# ESP32-P4 register map
Vendor: ESPRESSIF SYSTEMS (SHANGHAI) CO., LTD.; Series: ESP32 P-Series; File version: 2
CPU: RV32IMAFC r0p0, little endian, no MPU, FPU, 0 interrupt priority bits
Address unit: 32 bits
Registers are 32-bit, read-write, reset 0x0 unless marked. A register's access mark holds for its fields unless they carry their own. Offsets are from the block's base; [hi:lo] are bit positions; {n}, {i} and the like mark numbered series.

## TWAI0 — Two-Wire Automotive Interface
Base 0x500D7000
Same registers: TWAI1 0x500D8000, TWAI2 0x500D9000
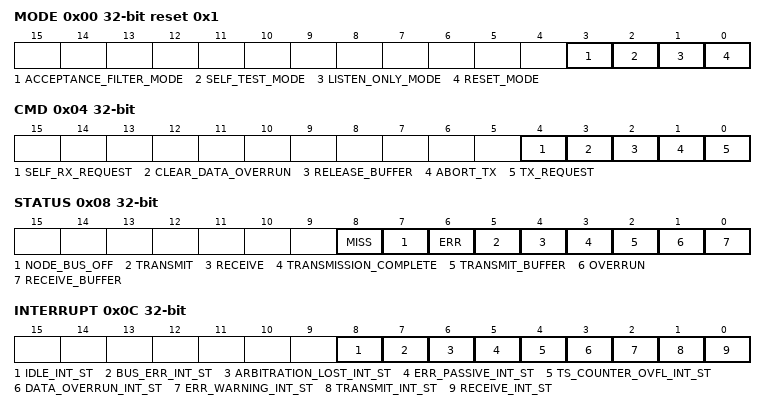
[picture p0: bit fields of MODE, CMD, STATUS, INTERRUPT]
0x00 MODE reset 0x1 — TWAI mode register.
  [3] ACCEPTANCE_FILTER_MODE — 1:single, the single acceptance filter option is enabled (one filter with the length of 32 bit is active). 0:dual, the dual acceptance filter option is enabled (two filters, each with the length of 16 bit are active).
  [2] SELF_TEST_MODE — 1: self test, in this mode a full node test is possible without any other active node on the bus using the self reception request command. The TWAI controller will perform a successful transmission, even if there is no acknowledge received. 0: normal, an acknowledge is required for successful transmission.
  [1] LISTEN_ONLY_MODE — 1: listen only, in this mode the TWAI controller would give no acknowledge to the TWAI-bus, even if a message is received successfully. The error counters are stopped at the current value. 0: normal.
  [0] RESET_MODE — 1: reset, detection of a set reset mode bit results in aborting the current transmission/reception of a message and entering the reset mode. 0: normal, on the '1-to-0' transition of the reset mode bit, the TWAI controller returns to the operating mode.
0x04 CMD wo — TWAI command register.
  [4] SELF_RX_REQUEST — 1: present, a message shall be transmitted and received simultaneously. 0: absent.
  [3] CLEAR_DATA_OVERRUN — 1: clear, the data overrun status bit is cleared. 0: no action.
  [2] RELEASE_BUFFER — 1: released, the receive buffer, representing the message memory space in the RXFIFO is released. 0: no action
  [1] ABORT_TX — 1: present, if not already in progress, a pending transmission request is cancelled. 0: absent
  [0] TX_REQUEST — 1: present, a message shall be transmitted. 0: absent
0x08 STATUS ro — TWAI status register.
  [8] MISS — 1: current message is destroyed because of FIFO overflow.
  [7] NODE_BUS_OFF — 1: bus-off, the TWAI controller is not involved in bus activities. 0: bus-on, the TWAI controller is involved in bus activities
  [6] ERR — 1: error, at least one of the error counters has reached or exceeded the CPU warning limit defined by the Error Warning Limit Register (EWLR). 0: ok, both error counters are below the warning limit
  [5] TRANSMIT — 1: transmit, the TWAI controller is transmitting a message. 0: idle
  [4] RECEIVE — 1: receive, the TWAI controller is receiving a message. 0: idle
  [3] TRANSMISSION_COMPLETE — 1: complete, last requested transmission has been successfully completed. 0: incomplete, previously requested transmission is not yet completed
  [2] TRANSMIT_BUFFER — 1: released, the CPU may write a message into the transmit buffer. 0: locked, the CPU cannot access the transmit buffer, a message is either waiting for transmission or is in the process of being transmitted
  [1] OVERRUN — 1: overrun, a message was lost because there was not enough space for that message in the RXFIFO. 0: absent, no data overrun has occurred since the last clear data overrun command was given
  [0] RECEIVE_BUFFER — 1: full, one or more complete messages are available in the RXFIFO. 0: empty, no message is available
0x0C INTERRUPT ro — Interrupt signals' register.
  [8] IDLE_INT_ST — 1: this bit is set when the TWAI controller detects state of TWAI become IDLE and this interrupt enable bit is set within the interrupt enable register. 0: reset
  [7] BUS_ERR_INT_ST — 1: this bit is set when the TWAI controller detects an error on the TWAI-bus and the BEIE bit is set within the interrupt enable register. 0: reset
  [6] ARBITRATION_LOST_INT_ST — 1: this bit is set when the TWAI controller lost the arbitration and becomes a receiver and the ALIE bit is set within the interrupt enable register. 0: reset
  [5] ERR_PASSIVE_INT_ST — 1: this bit is set whenever the TWAI controller has reached the error passive status (at least one error counter exceeds the protocol-defined level of 127) or if the TWAI controller is in the error passive status and enters the error active status again and the EPIE bit is set within the interrupt enable register. 0: reset
  [4] TS_COUNTER_OVFL_INT_ST — 1: this bit is set then the timestamp counter reaches the maximum value and overflow.
  [3] DATA_OVERRUN_INT_ST — 1: this bit is set on a '0-to-1' transition of the data overrun status bit and the DOIE bit is set within the interrupt enable register. 0: reset
  [2] ERR_WARNING_INT_ST — 1: this bit is set on every change (set and clear) of either the error status or bus status bits and the EIE bit is set within the interrupt enable register. 0: reset
  [1] TRANSMIT_INT_ST — 1: this bit is set whenever the transmit buffer status changes from '0-to-1' (released) and the TIE bit is set within the interrupt enable register. 0: reset
  [0] RECEIVE_INT_ST — 1: this bit is set while the receive FIFO is not empty and the RIE bit is set within the interrupt enable register. 0: reset
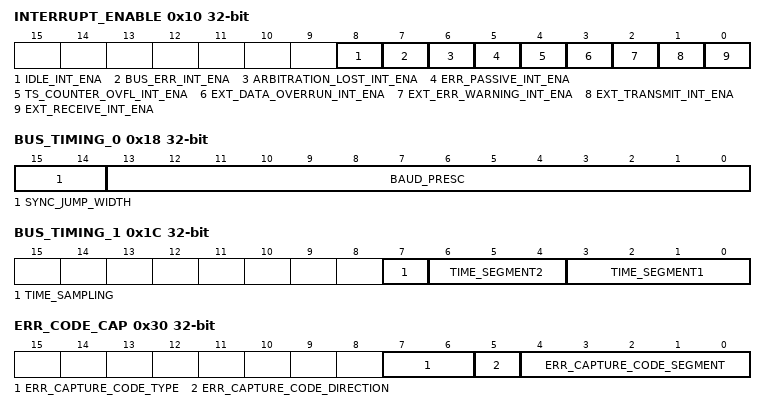
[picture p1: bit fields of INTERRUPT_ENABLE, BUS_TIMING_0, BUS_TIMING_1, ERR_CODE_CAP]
0x10 INTERRUPT_ENABLE access per field
  [8] IDLE_INT_ENA ro — 1: enabled, if state of TWAI become IDLE, the TWAI controller requests the respective interrupt. 0: disable
  [7] BUS_ERR_INT_ENA rw — 1: enabled, if an bus error has been detected, the TWAI controller requests the respective interrupt. 0: disable
  [6] ARBITRATION_LOST_INT_ENA rw — 1: enabled, if the TWAI controller has lost arbitration, the respective interrupt is requested. 0: disable
  [5] ERR_PASSIVE_INT_ENA rw — 1: enabled, if the error status of the TWAI controller changes from error active to error passive or vice versa, the respective interrupt is requested. 0: disable
  [4] TS_COUNTER_OVFL_INT_ENA rw — enable the timestamp counter overflow interrupt request.
  [3] EXT_DATA_OVERRUN_INT_ENA rw — 1: enabled, if the data overrun status bit is set (see status register. Table 14), the TWAI controllerrequests the respective interrupt. 0: disable
  [2] EXT_ERR_WARNING_INT_ENA rw — 1: enabled, if the error or bus status change (see status register. Table 14), the TWAI controllerrequests the respective interrupt. 0: disable
  [1] EXT_TRANSMIT_INT_ENA rw — 1: enabled, when a message has been successfully transmitted or the transmit buffer is accessible again (e.g. after an abort transmission command), the TWAI controller requests the respective interrupt. 0: disable
  [0] EXT_RECEIVE_INT_ENA rw — 1: enabled, when the receive buffer status is 'full' the TWAI controller requests the respective interrupt. 0: disable
0x18 BUS_TIMING_0 — Bit timing configuration register 0.
  [15:14] SYNC_JUMP_WIDTH — The synchronization jump width defines the maximum number of clock cycles a bit period may be shortened or lengthened. Software has R/W permission in reset mode and RO in operation mode.
  [13:0] BAUD_PRESC — The period of the TWAI system clock is programmable and determines the individual bit timing. Software has R/W permission in reset mode and RO permission in operation mode.
0x1C BUS_TIMING_1 — Bit timing configuration register 1.
  [7] TIME_SAMPLING — 1: triple, the bus is sampled three times. 0: single, the bus is sampled once. Software has R/W permission in reset mode and RO in operation mode.
  [6:4] TIME_SEGMENT2 — The number of clock cycles in TSEG2 per bit timing. Software has R/W permission in reset mode and RO in operation mode.
  [3:0] TIME_SEGMENT1 — The number of clock cycles in TSEG1 per bit timing. Software has R/W permission in reset mode and RO in operation mode.
0x2C ARB_LOST_CAP ro — TWAI arbiter lost capture register.
  [4:0] ARBITRATION_LOST_CAPTURE — This register contains information about the bit position of losing arbitration.
0x30 ERR_CODE_CAP ro — TWAI error info capture register.
  [7:6] ERR_CAPTURE_CODE_TYPE — 00: bit error. 01: form error. 10:stuff error. 11:other type of error.
  [5] ERR_CAPTURE_CODE_DIRECTION — 1: RX, error occurred during reception. 0: TX, error occurred during transmission.
  [4:0] ERR_CAPTURE_CODE_SEGMENT — This register contains information about the location of errors on the bus.
0x34 ERR_WARNING_LIMIT reset 0x60 — TWAI error threshold configuration register.
  [7:0] ERR_WARNING_LIMIT — The threshold that trigger error warning interrupt when this interrupt is enabled. Software has R/W permission in reset mode and RO in operation mode.
0x38 RX_ERR_CNT — Rx error counter register.
  [7:0] RX_ERR_CNT — The RX error counter register reflects the current value of the transmit error counter. Software has R/W permission in reset mode and RO in operation mode.
0x3C TX_ERR_CNT — Tx error counter register.
  [7:0] TX_ERR_CNT — The TX error counter register reflects the current value of the transmit error counter. Software has R/W permission in reset mode and RO in operation mode.
{0x40+4i} DATA_{i} (i=0..3) — Data register {i}.
  [7:0] DATA_{i} — In reset mode, it is acceptance code register {i} with R/W Permission. In operation mode, when software initiate write operation, it is tx data register {i} and when software initiate read operation, it is rx data register {i}.
{0x40+4i} DATA_{i} (i=4..7) — Data register {i}.
  [7:0] DATA_{i} — In reset mode, it is acceptance mask register {i-4} with R/W Permission. In operation mode, when software initiate write operation, it is tx data register {i} and when software initiate read operation, it is rx data register {i}.
{0x40+4i} DATA_{i} (i=8..12) — Data register {i}.
  [7:0] DATA_{i} — In reset mode, reserved with RO. In operation mode, when software initiate write operation, it is tx data register {i} and when software initiate read operation, it is rx data register {i}.
0x74 RX_MESSAGE_COUNTER ro — Received message counter register.
  [6:0] RX_MESSAGE_COUNTER — Reflects the number of messages available within the RXFIFO. The value is incremented with each receive event and decremented by the release receive buffer command.
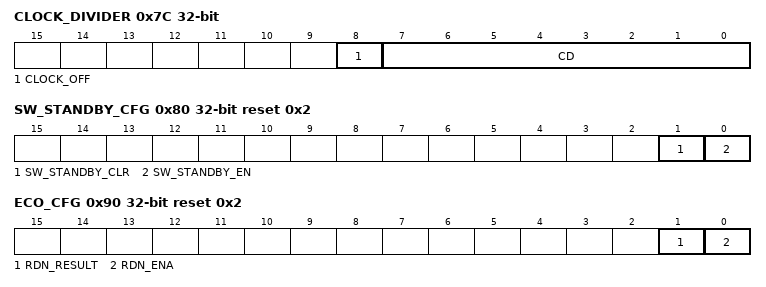
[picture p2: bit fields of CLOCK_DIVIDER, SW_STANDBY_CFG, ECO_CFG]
0x7C CLOCK_DIVIDER
  [8] CLOCK_OFF — 1: Disable the external CLKOUT pin. 0: Enable the external CLKOUT pin. Software has R/W permission in reset mode and RO in operation mode.
  [7:0] CD — These bits are used to define the frequency at the external CLKOUT pin.
0x80 SW_STANDBY_CFG reset 0x2 — Software configure standby pin directly.
  [1] SW_STANDBY_CLR — Clear standby pin.
  [0] SW_STANDBY_EN — Enable standby pin.
0x84 HW_CFG — Hardware configure standby pin.
  [0] HW_STANDBY_EN — Enable function that hardware control standby pin.
0x88 HW_STANDBY_CNT reset 0x1 — Configure standby counter.
  [31:0] STANDBY_WAIT_CNT — Configure the number of cycles before standby becomes high when TWAI_HW_STANDBY_EN is enabled.
0x8C IDLE_INTR_CNT reset 0x1 — Configure idle interrupt counter.
  [31:0] IDLE_INTR_CNT — Configure the number of cycles before triggering idle interrupt.
0x90 ECO_CFG access per field reset 0x2 — ECO configuration register.
  [1] RDN_RESULT ro — Output of eco module.
  [0] RDN_ENA rw — Enable eco module.
0x94 TIMESTAMP_DATA ro
  [31:0] TIMESTAMP_DATA — Data of timestamp of a CAN frame.
0x98 TIMESTAMP_PRESCALER reset 0x1F — Timestamp configuration register
  [15:0] TS_DIV_NUM — Configures the clock division number of timestamp counter.
0x9C TIMESTAMP_CFG — Timestamp configuration register
  [0] TS_ENABLE — enable the timestamp collection function.
